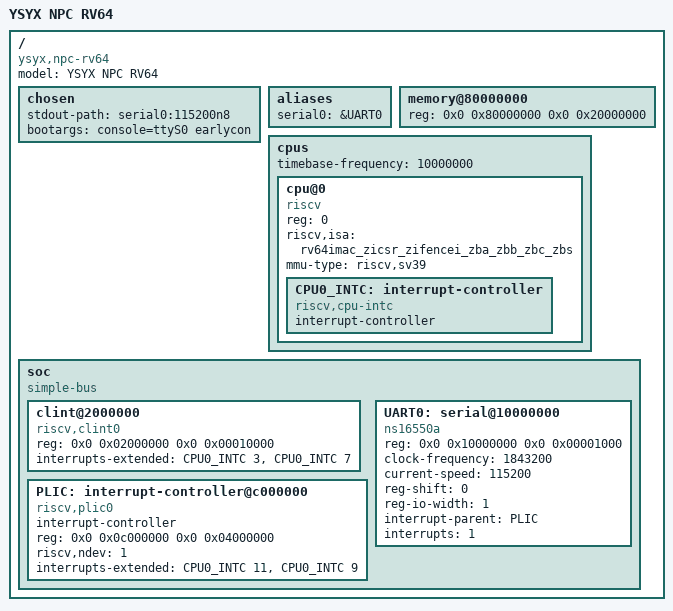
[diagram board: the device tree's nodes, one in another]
/dts-v1/;

/ {
  #address-cells = <2>;
  #size-cells = <2>;
  compatible = "ysyx,npc-rv64";
  model = "YSYX NPC RV64";

  chosen {
    stdout-path = "serial0:115200n8";
    bootargs = "console=ttyS0 earlycon";
  };

  aliases {
    serial0 = &UART0;
  };

  memory@80000000 {
    device_type = "memory";
    reg = <0x0 0x80000000 0x0 0x20000000>;
  };

  cpus {
    #address-cells = <1>;
    #size-cells = <0>;
    timebase-frequency = <10000000>;

    cpu@0 {
      device_type = "cpu";
      reg = <0>;
      status = "okay";
      compatible = "riscv";
      riscv,isa = "rv64imac_zicsr_zifencei_zba_zbb_zbc_zbs";
      mmu-type = "riscv,sv39";

      CPU0_INTC: interrupt-controller {
        #interrupt-cells = <1>;
        interrupt-controller;
        compatible = "riscv,cpu-intc";
      };
    };
  };

  soc {
    #address-cells = <2>;
    #size-cells = <2>;
    compatible = "simple-bus";
    ranges;

    clint@2000000 {
      compatible = "riscv,clint0";
      reg = <0x0 0x02000000 0x0 0x00010000>;
      interrupts-extended = <&CPU0_INTC 3 &CPU0_INTC 7>;
    };

    PLIC: interrupt-controller@c000000 {
      #interrupt-cells = <1>;
      interrupt-controller;
      compatible = "riscv,plic0";
      reg = <0x0 0x0c000000 0x0 0x04000000>;
      riscv,ndev = <1>;
      interrupts-extended = <&CPU0_INTC 11 &CPU0_INTC 9>;
    };

    UART0: serial@10000000 {
      compatible = "ns16550a";
      reg = <0x0 0x10000000 0x0 0x00001000>;
      clock-frequency = <1843200>;
      current-speed = <115200>;
      reg-shift = <0>;
      reg-io-width = <1>;
      interrupt-parent = <&PLIC>;
      interrupts = <1>;
    };
  };
};
